# LPC112x register map
File version: 0.3
CPU: CM0 r0p0, little endian, no MPU, no FPU, 2 interrupt priority bits
Registers are 32-bit, read-write, reset 0x0 unless marked. A register's access mark holds for its fields unless they carry their own. Offsets are from the block's base; [hi:lo] are bit positions; {n}, {i} and the like mark numbered series.

## SYSCON — System configuration (SYSCON)
Base 0x40048000
0x00 SYSMEMREMAP reset 0x2 — System memory remap
  [1:0] MAP
    0=BOOT_LOADER_MODE (Boot Loader Mode. Interrupt vectors are re-mapped to Boot ROM.); 1=USER_RAM_MODE (User RAM Mode. Interrupt vectors are re-mapped to Static RAM.); 2=USER_FLASH_MODE (User Flash Mode. Interrupt vectors are not re-mapped and reside in Flash.)
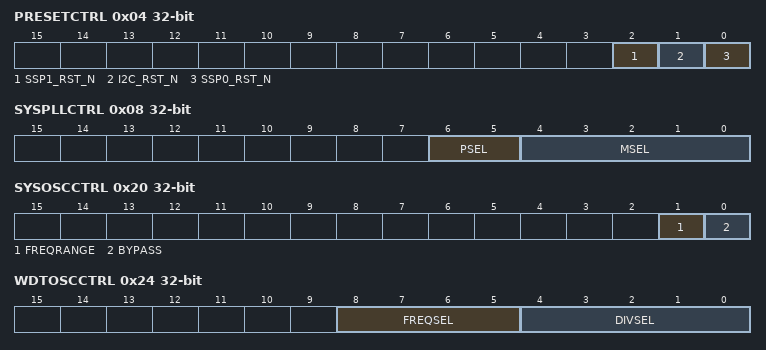
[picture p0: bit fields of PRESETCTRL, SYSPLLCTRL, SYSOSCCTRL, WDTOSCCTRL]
0x04 PRESETCTRL — Peripheral reset control
  [2] SSP1_RST_N — SSP1 reset control
    0=RESET (Reset. Resets the SSP1 peripheral.); 1=CLEAR (Clear. SSP1 reset de-asserted.)
  [1] I2C_RST_N — I2C reset control
    0=RESET (Reset. Resets the I2C peripheral.); 1=CLEAR (Clear. I2C reset de-asserted.)
  [0] SSP0_RST_N — SSP0 reset control
    0=RESET (Reset. Resets the SSP0 peripheral.); 1=CLEAR (Clear. SSP0 reset de-asserted.)
0x08 SYSPLLCTRL — System PLL control
  [6:5] PSEL — Post divider ratio P. The division ratio is 2 x P.
    0=P_EQ_1 (P = 1); 1=P_EQ_2 (P = 2); 2=P_EQ_4 (P = 4); 3=P_EQ_8 (P = 8)
  [4:0] MSEL — Feedback divider value. The division value M is the programmed MSEL value + 1. 00000: Division ratio M = 1 to 11111: Division ratio M = 32.
0x0C SYSPLLSTAT ro — System PLL status
  [0] LOCK — PLL lock status
    0=PLL_NOT_LOCKED; 1=PLL_LOCKED
0x20 SYSOSCCTRL — System oscillator control
  [1] FREQRANGE — Determines frequency range for Low-power oscillator.
    0=LOW (Low. 1 - 20 MHz frequency range.); 1=HIGH (High. 15 - 25 MHz frequency range)
  [0] BYPASS — Bypass system oscillator
    0=OSCILLATOR_IS_NOT_BY (Oscillator is not bypassed.); 1=BYPASS_ENABLED (Bypass enabled. PLL input (sys_osc_clk) is fed directly from the XTALIN pin bypassing the oscillator. Use this mode when using an external clock source instead of the crystal oscillator.)
0x24 WDTOSCCTRL — Watchdog oscillator control
  [8:5] FREQSEL — Select watchdog oscillator analog output frequency (Fclkana).
    1=0.6 MHz; 2=1.05 MHz; 3=1.4 MHz; 4=1.75 MHz; 5=2.1 MHz; 6=2.4 MHz; 7=2.7 MHz; 8=3.0 MHz; 9=3.25 MHz; 10=3.5 MHz; 11=3.75 MHz; 12=4.0 MHz; 13=4.2 MHz; 14=4.4 MHz; 15=4.6 MHz
  [4:0] DIVSEL — Select divider for Fclkana. wdt_osc_clk = Fclkana/ (2 x (1 + DIVSEL)) 00000: 2 x (1 + DIVSEL) = 2 00001: 2 x (1 + DIVSEL) = 4 to 11111: 2 x (1 + DIVSEL) = 64
0x28 IRCCTRL reset 0x80 — IRC control
  [7:0] TRIM — Trim value
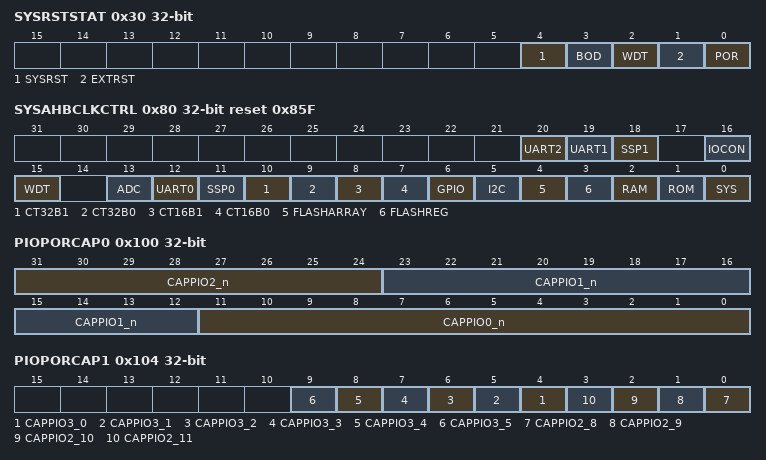
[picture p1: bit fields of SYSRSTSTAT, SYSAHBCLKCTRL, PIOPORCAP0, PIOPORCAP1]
0x30 SYSRSTSTAT — System reset status register
  [4] SYSRST — Status of the software system reset
    0=NO_SYSTEM_RESET_DETE (No System reset detected.); 1=SYSTEM_RESET_DETECTE (System reset detected. Writing a one clears this reset.)
  [3] BOD — Status of the Brown-out detect reset
    0=NO_BOD_RESET_DETECTE (No BOD reset detected.); 1=BOD_RESET_DETECTED (BOD reset detected. Writing a one clears this reset.)
  [2] WDT — Status of the Watchdog reset
    0=NO_WDT_RESET_DETECTE (No WDT reset detected.); 1=WDT_RESET_DETECTED (WDT reset detected. Writing a one clears this reset.)
  [1] EXTRST — Status of the external RESET pin.
    0=NO_RESET_EVENT_DETEC (No RESET event detected.); 1=RESET_DETECTED (RESET detected. Writing a one clears this reset.)
  [0] POR — POR reset status
    0=NO_POR_DETECTED; 1=POR_DETECTED (POR detected. Writing a one clears this reset.)
0x40 SYSPLLCLKSEL — System PLL clock source select
  [1:0] SEL — System PLL clock source
    0=IRC_OSCILLATOR; 1=SYSTEM_OSCILLATOR
0x44 SYSPLLCLKUEN — System PLL clock source update enable
  [0] ENA — Enable system PLL clock source update
    0=NO_CHANGE; 1=UPDATE_CLOCK_SOURCE
0x70 MAINCLKSEL — Main clock source select
  [1:0] SEL — Clock source for main clock
    0=IRC_OSCILLATOR; 1=PLL_INPUT (PLL input. Input clock to system PLL); 2=WDT_OSCILLATOR; 3=PLL_OUTPUT (PLL output. System PLL clock out)
0x74 MAINCLKUEN — Main clock source update enable
  [0] ENA — Enable main clock source update
    0=NO_CHANGE; 1=UPDATE_CLOCK_SOURCE
0x78 SYSAHBCLKDIV reset 0x1 — System AHB clock divider
  [7:0] DIV — System AHB clock divider values 0: System clock disabled. 1: Divide by 1. to 255: Divide by 255.
0x80 SYSAHBCLKCTRL reset 0x85F — System AHB clock control
  [20] UART2 — Enables clock for UART2.
    0=DISABLE; 1=ENABLE
  [19] UART1 — Enables clock for UART1.
    0=DISABLE; 1=ENABLE
  [18] SSP1 — Enables clock for SSP1.
    0=DISABLE; 1=ENABLE
  [16] IOCON — Enables clock for I/O configuration block.
    0=DISABLE; 1=ENABLE
  [15] WDT — Enables clock for WWDT.
    0=DISABLE; 1=ENABLE
  [13] ADC — Enables clock for 12-bit ADC.
    0=DISABLE; 1=ENABLE
  [12] UART0 — Enables clock for UART0.
    0=DISABLE; 1=ENABLE
  [11] SSP0 — Enables clock for SSP0.
    0=DISABLE; 1=ENABLE
  [10] CT32B1 — Enables clock for 32-bit counter/timer 1.
    0=DISABLE; 1=ENABLE
  [9] CT32B0 — Enables clock for 32-bit counter/timer 0.
    0=DISABLE; 1=ENABLE
  [8] CT16B1 — Enables clock for 16-bit counter/timer 1.
    0=DISABLE; 1=ENABLE
  [7] CT16B0 — Enables clock for 16-bit counter/timer 0.
    0=DISABLE; 1=ENABLE
  [6] GPIO — Enables clock for GPIO.
    0=DISABLE; 1=ENABLE
  [5] I2C — Enables clock for I2C.
    0=DISABLE; 1=ENABLE
  [4] FLASHARRAY — Enables clock for flash array access.
    0=DISABLED; 1=ENABLED
  [3] FLASHREG — Enables clock for flash register interface.
    0=DISABLED; 1=ENABLED
  [2] RAM — Enables clock for RAM.
    0=DISABLE; 1=ENABLE
  [1] ROM — Enables clock for ROM.
    0=DISABLE; 1=ENABLE
  [0] SYS — Enables clock for AHB to APB bridge, to the AHB matrix, to the Cortex-M0 FCLK and HCLK, to the SysCon, and to the PMU. This bit is read only.
    1=ENABLE
0x94 SSP0CLKDIV — SSP0 clock divider
  [7:0] DIV — SSP0_PCLK clock divider values 0: Disable SSP0_PCLK. 1: Divide by 1. to 255: Divide by 255.
0x98 UART0CLKDIV — UART0 clock divider
  [7:0] DIV — UART0_PCLK clock divider values 0: Disable UART0_PCLK. 1: Divide by 1. to 255: Divide by 255.
0x9C SSP1CLKDIV — SSP1 clock divider
  [7:0] DIV — SSP1_PCLK clock divider values 0: Disable SSP1_PCLK. 1: Divide by 1. to 255: Divide by 255.
0xA0 UART1CLKDIV — UART1 clock divider
  [7:0] DIV — UART1_PCLK clock divider values 0: Disable UART1_PCLK. 1: Divide by 1. to 255: Divide by 255.
0xA4 UART2CLKDIV — UART2 clock divider
  [7:0] DIV — UART2_PCLK clock divider values 0: Disable UART2_PCLK. 1: Divide by 1. to 255: Divide by 255.
0xD0 WDTCLKSEL — WDT clock source select
  [1:0] SEL — WDT clock source
    0=IRC_OSCILLATOR; 1=MAIN_CLOCK; 2=WATCHDOG_OSCILLATOR
0xD4 WDTCLKUEN — WDT clock source update enable
  [0] ENA — Enable WDT clock source update
    0=NO_CHANGE; 1=UPDATE_CLOCK_SOURCE
0xD8 WDTCLKDIV — WDT clock divider
  [7:0] DIV — WDT clock divider values 0: Disable WDCLK. 1: Divide by 1. to 255: Divide by 255.
0xE0 CLKOUTCLKSEL — CLKOUT clock source select
  [1:0] SEL — CLKOUT clock source
    0=IRC_OSCILLATOR; 1=SYSTEM_OSCILLATOR; 2=WATCHDOG_OSCILLATOR; 3=MAIN_CLOCK
0xE4 CLKOUTUEN — CLKOUT clock source update enable
  [0] ENA — Enable CLKOUT clock source update
    0=NO_CHANGE; 1=UPDATE_CLOCK_SOURCE
0xE8 CLKOUTCLKDIV — CLKOUT clock divider
  [7:0] DIV — Clock output divider values 0: Disable CLKOUT. 1: Divide by 1. to 255: Divide by 255.
0x100 PIOPORCAP0 ro reset not defined — POR captured PIO status 0
  [31:24] CAPPIO2_n — Raw reset status input PIO2_n: PIO2_7 to PIO2_0
  [23:12] CAPPIO1_n — Raw reset status input PIO1_n: PIO1_11 to PIO1_0
  [11:0] CAPPIO0_n — Raw reset status input PIO0_n: PIO0_11 to PIO0_0
0x104 PIOPORCAP1 ro reset not defined — POR captured PIO status 1
  [n+4] CAPPIO3_{n} (n=0..5) — Raw reset status input PIO3_{n}
  [n-8] CAPPIO2_{n} (n=8..11) — Raw reset status input PIO2_{n}
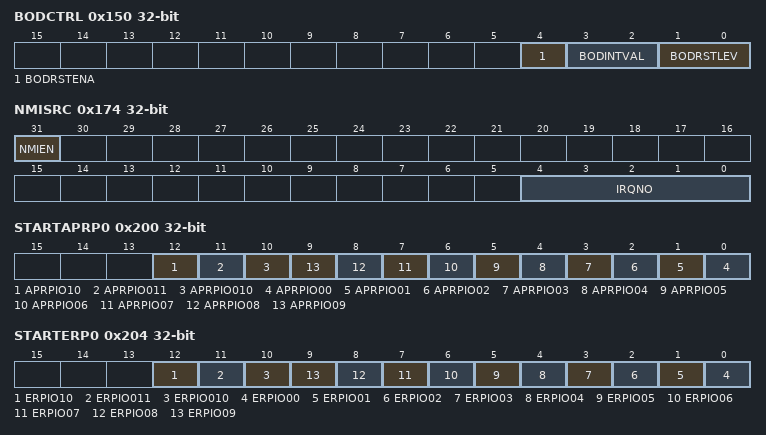
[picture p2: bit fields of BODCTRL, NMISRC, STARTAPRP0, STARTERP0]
0x150 BODCTRL — BOD control
  [4] BODRSTENA — BOD reset enable
    0=DISABLE_RESET_FUNCTI (Disable reset function.); 1=ENABLE_RESET_FUNCTIO (Enable reset function.)
  [3:2] BODINTVAL — BOD interrupt level
    1=LEVEL_1 (Level 1.The interrupt assertion threshold voltage is 2.22 V; the interrupt de-assertion threshold voltage is 2.35 V.); 2=LEVEL_2 (Level 2. The interrupt assertion threshold voltage is 2.52 V; the interrupt de-assertion threshold voltage is 2.66 V.); 3=LEVEL_3 (Level 3. The interrupt assertion threshold voltage is 2.80 V; the interrupt de-assertion threshold voltage is 2.90 V.)
  [1:0] BODRSTLEV — BOD reset level
    0=LEVEL_0 (Level 0. The reset assertion threshold voltage is 1.46 V; the reset de-assertion threshold voltage is 1.63 V.); 1=LEVEL_1 (Level 1. The reset assertion threshold voltage is 2.06 V; the reset de-assertion threshold voltage is 2.15 V.); 2=LEVEL_2 (Level 2. The reset assertion threshold voltage is 2.35 V; the reset de-assertion threshold voltage is 2.43 V.); 3=LEVEL_3 (Level 3. The reset assertion threshold voltage is 2.63 V; the reset de-assertion threshold voltage is 2.71 V.)
0x154 SYSTCKCAL reset 0x4 — System tick counter calibration
  [25:0] CAL — System tick timer calibration value
0x170 IRQLATENCY reset 0x10 — IQR delay. Allows trade-off between interrupt latency and determinism.
  [7:0] LATENCY — 8-bit latency value
0x174 NMISRC — NMI source selection
  [31] NMIEN — Write a 1 to this bit to enable the Non-Maskable Interrupt (NMI) source selected by bits 4:0.
  [4:0] IRQNO — The IRQ number of the interrupt that acts as the Non-Maskable Interrupt (NMI) if bit 31 in this register is 1.
0x200 STARTAPRP0 reset not defined — Start logic edge control register 0
  [12] APRPIO10 — 0 = Falling edge 1 = Rising edge
  [11] APRPIO011 — 0 = Falling edge 1 = Rising edge
  [10] APRPIO010 — 0 = Falling edge 1 = Rising edge
  [n] APRPIO{n:02} (n=0..9) — 0 = Falling edge 1 = Rising edge
0x204 STARTERP0 reset not defined — Start logic signal enable register 0
  [12] ERPIO10 — 0 = Disabled 1 = Enabled
  [11] ERPIO011 — 0 = Disabled 1 = Enabled
  [10] ERPIO010 — 0 = Disabled 1 = Enabled
  [n] ERPIO{n:02} (n=0..9) — 0 = Disabled 1 = Enabled
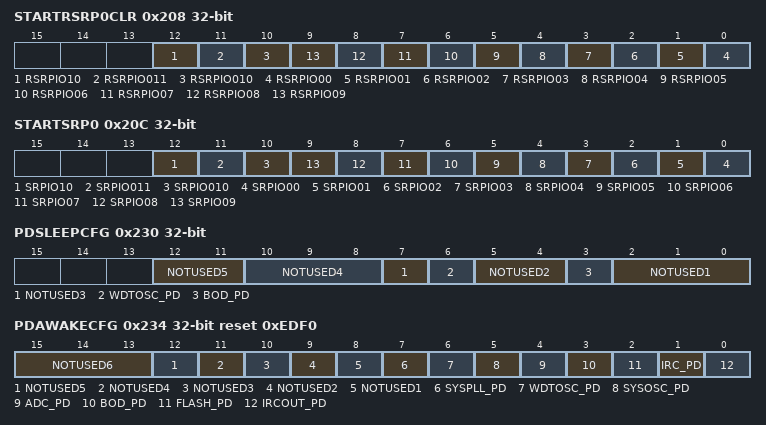
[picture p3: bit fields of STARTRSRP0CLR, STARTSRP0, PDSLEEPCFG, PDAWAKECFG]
0x208 STARTRSRP0CLR wo reset not defined — Start logic reset register 0
  [12] RSRPIO10 — 0 = Do nothing. 1 = Writing 1 resets the start signal.
  [11] RSRPIO011 — 0 = Do nothing. 1 = Writing 1 resets the start signal.
  [10] RSRPIO010 — 0 = Do nothing. 1 = Writing 1 resets the start signal.
  [n] RSRPIO{n:02} (n=0..9) — 0 = Do nothing. 1 = Writing 1 resets the start signal.
0x20C STARTSRP0 ro reset not defined — Start logic status register 0
  [12] SRPIO10 — 0 = No start signal received. 1 = Start signal pending.
  [11] SRPIO011 — 0 = No start signal received. 1 = Start signal pending.
  [10] SRPIO010 — 0 = No start signal received. 1 = Start signal pending.
  [n] SRPIO{n:02} (n=0..9) — 0 = No start signal received. 1 = Start signal pending.
0x230 PDSLEEPCFG — Power-down states in Deep-sleep mode
  [12:11] NOTUSED5 — Reserved. Always write these bits as 11.
  [10:8] NOTUSED4 — Reserved. Always write these bits as 000.
  [7] NOTUSED3 — Reserved. Always write this bit as 1.
  [6] WDTOSC_PD — Watchdog oscillator power control in Deep-sleep mode, see Table 41.
    0=POWERED; 1=POWERED_DOWN
  [5:4] NOTUSED2 — Reserved. Always write these bits as 11.
  [3] BOD_PD — BOD power-down control in Deep-sleep mode, see Table 41.
    0=POWERED; 1=POWERED_DOWN
  [2:0] NOTUSED1 — Reserved. Always write these bits as 111.
0x234 PDAWAKECFG reset 0xEDF0 — Power-down states after wake-up from Deep-sleep mode
  [15:13] NOTUSED6 — Reserved. Always write these bits as 111.
  [12] NOTUSED5 — Reserved. Always write this bit as 0.
  [11] NOTUSED4 — Reserved. Always write this bit as 1.
  [10] NOTUSED3 — Reserved. Always write this bit as 1.
  [9] NOTUSED2 — Reserved. Always write this bit as 0.
  [8] NOTUSED1 — Reserved. Always write this bit as 1.
  [7] SYSPLL_PD — System PLL wake-up configuration
    0=POWERED; 1=POWERED_DOWN
  [6] WDTOSC_PD — Watchdog oscillator wake-up configuration
    0=POWERED; 1=POWERED_DOWN
  [5] SYSOSC_PD — System oscillator wake-up configuration
    0=POWERED; 1=POWERED_DOWN
  [4] ADC_PD — ADC wake-up configuration
    0=POWERED; 1=POWERED_DOWN
  [3] BOD_PD — BOD wake-up configuration
    0=POWERED; 1=POWERED_DOWN
  [2] FLASH_PD — Flash wake-up configuration
    0=POWERED; 1=POWERED_DOWN
  [1] IRC_PD — IRC oscillator power-down wake-up configuration
    0=POWERED; 1=POWERED_DOWN
  [0] IRCOUT_PD — IRC oscillator output wake-up configuration
    0=POWERED; 1=POWERED_DOWN
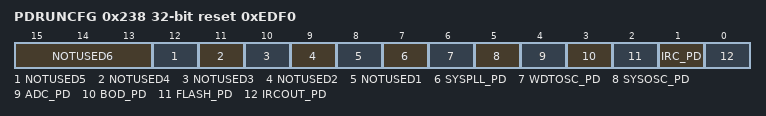
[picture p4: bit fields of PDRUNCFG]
0x238 PDRUNCFG reset 0xEDF0 — Power-down configuration register
  [15:13] NOTUSED6 — Reserved. Always write these bits as 111.
  [12] NOTUSED5 — Reserved. Always write this bit as 0.
  [11] NOTUSED4 — Reserved. Always write this bit as 1.
  [10] NOTUSED3 — Reserved. Always write this bit as 1.
  [9] NOTUSED2 — Reserved. Always write this bit as 0.
  [8] NOTUSED1 — Reserved. Always write this bit as 1.
  [7] SYSPLL_PD — System PLL power-down
    0=POWERED; 1=POWERED_DOWN
  [6] WDTOSC_PD — Watchdog oscillator power-down
    0=POWERED; 1=POWERED_DOWN
  [5] SYSOSC_PD — System oscillator power-down
    0=POWERED; 1=POWERED_DOWN
  [4] ADC_PD — ADC power-down
    0=POWERED; 1=POWERED_DOWN
  [3] BOD_PD — BOD power-down
    0=POWERED; 1=POWERED_DOWN
  [2] FLASH_PD — Flash power-down
    0=POWERED; 1=POWERED_DOWN
  [1] IRC_PD — IRC oscillator power-down
    0=POWERED; 1=POWERED_DOWN
  [0] IRCOUT_PD — IRC oscillator output power-down
    0=POWERED; 1=POWERED_DOWN
